# STM32H523 register map
File version: 1.2
CPU: CM33 r0p0, little endian, MPU, FPU, 4 interrupt priority bits
Registers are 32-bit, read-write, reset 0x0 unless marked. A register's access mark holds for its fields unless they carry their own. Offsets are from the block's base; [hi:lo] are bit positions; {n}, {i} and the like mark numbered series.

## DLYBOS1 — DLYB address block description
Base 0x4600F000
Same registers: DLYBSD1 0x46008400, DLYBSD1_S 0x56008400, DLYBOS1_S 0x5600F000
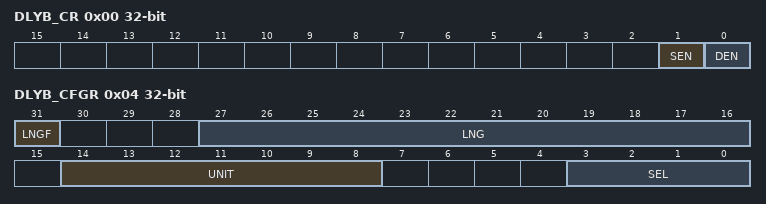
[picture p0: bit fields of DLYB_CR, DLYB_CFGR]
0x00 DLYB_CR — DLYB control register
  [1] SEN — Sampler length enable bit
    0=Sampler length and register access to UNIT[6:0] and SEL[3:0] disabled, output clock enabled; 1=Sampler length and register access to UNIT[6:0] and SEL[3:0] enabled, output clock disabled
  [0] DEN — Delay block enable bit
    0=DLYB disabled; 1=DLYB enabled
0x04 DLYB_CFGR — DLYB configuration register
  [31] LNGF ro — Length valid flag
    0=Length value in LNG is not valid; 1=Length value in LNG is valid
  [27:16] LNG ro — Delay line length value
  [14:8] UNIT — Delay of a unit delay cell.
  [3:0] SEL — Phase for the output clock.

## HASH — HASH register bank
Base 0x420C0400
Same registers: HASH_S 0x520C0400
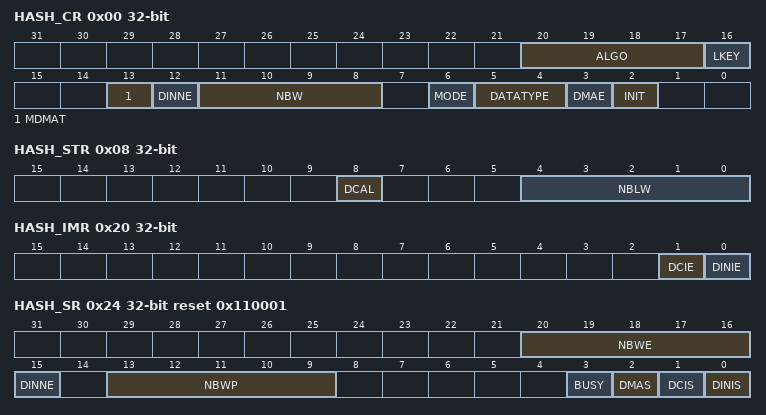
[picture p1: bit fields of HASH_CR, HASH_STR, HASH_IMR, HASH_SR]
0x00 HASH_CR — HASH control register
  [20:17] ALGO — Algorithm selection
    0=SHA-1; 2=SHA2-224; 3=SHA2-256; 12=SHA2-384; 13=SHA2-512/224; 14=SHA2-512/256; 15=SHA2-512
  [16] LKEY — Long key selection
    0=HMAC key is shorter or equal to the block size (short key); 1=HMAC key is longer than the block size (long key)
  [13] MDMAT — Multiple DMA transfers
    0=DCAL is automatically set at the end of a DMA transfer; 1=DCAL is not automatically set at the end of a DMA transfer
  [12] DINNE ro — DIN not empty
  [11:8] NBW ro — Number of words already pushed
  [6] MODE — Mode selection
    0=Hash mode selected; 1=HMAC mode selected
  [5:4] DATATYPE — Data type selection
    0=32-bit data; 1=16-bit data or half-word; 2=8-bit data or bytes; 3=bit data or bit string
  [3] DMAE — DMA enable
    0=DMA transfers disabled; 1=DMA transfers enabled
  [2] INIT — Initialize message digest calculation
0x04 HASH_DIN wo — HASH data input register
  [31:0] DATAIN — Data input
0x08 HASH_STR — HASH start register
  [8] DCAL — Digest calculation
  [4:0] NBLW — Number of valid bits in the last word
    0=All the 32 bits of the last data written are valid message bits, that is M[31:0]; 1=Only one bit of the last data written (after swapping) is valid, that is M[0]; 2=Only two bits of the last data written (after swapping) are valid, that is M[1:0]; 3=Only three bits of the last data written (after swapping) are valid that is M[2:0]; 31=Only 31 bits of the last data written (after swapping) are valid that is M[30:0]
{0xC+4i} HASH_HRA{i} ro (i=0..4) — HASH aliased digest register {i}
  [31:0] H{i} — Hash data x
0x20 HASH_IMR — HASH interrupt enable register
  [1] DCIE — Digest calculation completion interrupt enable
    0=Digest calculation completion interrupt disabled; 1=Digest calculation completion interrupt enabled
  [0] DINIE — Data input interrupt enable
    0=Data input interrupt disabled; 1=Data input interrupt enabled
0x24 HASH_SR reset 0x110001 — HASH status register
  [20:16] NBWE ro — Number of words expected
  [15] DINNE ro — DIN not empty
    0=No data are present in the data input buffer; 1=The input buffer contains at least one word of data
  [13:9] NBWP ro — Number of words already pushed
  [3] BUSY ro — Busy bit
    0=No block is currently being processed; 1=The hash core is processing a block of data
  [2] DMAS ro — DMA Status
    0=DMA interface is disabled (DMAE = 0) and no transfer is ongoing; 1=DMA interface is enabled (DMAE = 1) or a transfer is ongoing
  [1] DCIS — Digest calculation completion interrupt status
    0=No digest available in the HASH_HRx registers (zeros are returned); 1=Digest calculation complete, a digest is available in the HASH_HRx registers
  [0] DINIS — Data input interrupt status
    0=Less than 16 locations are free in the input buffer; 1=A new block can be entered into the input buffer
{0xF8+4i} HASH_CSR{i} (i=0..102) — HASH context swap register {i}
  [31:0] CS{i} — Context swap x
{0x310+4i} HASH_HR{i} ro (i=0..4) — HASH digest register {i}
  [31:0] H{i} — Hash data x
{0x310+4i} HASH_HR{i} ro (i=5..15) — HASH supplementary digest register {i}
  [31:0] H{i} — Hash data x

## Notices in the file
Copyright (c) 2025 STMicroelectronics.
SPDX-License-Identifier: Apache-2.0
Licensed under the Apache License, Version 2.0 (the "License");
you may not use this file except in compliance with the License.
You may obtain a copy of the License at
http://www.apache.org/licenses/LICENSE-2.0
Unless required by applicable law or agreed to in writing, software
distributed under the License is distributed on an "AS IS" BASIS,
WITHOUT WARRANTIES OR CONDITIONS OF ANY KIND, either express or implied.
See the License for the specific language governing permissions and
limitations under the License.
